# RN831X_RN861X_MCU register map
File version: v0.0.1
CPU: RN831X_RN861X_MCU r1p0, little endian, MPU, no FPU
Registers are 32-bit, read-write, reset 0x0 unless marked. A register's access mark holds for its fields unless they carry their own. Offsets are from the block's base; [hi:lo] are bit positions; {n}, {i} and the like mark numbered series.

## AES_CORE0 — AES module
Base 0x30014000
Same registers: AES_CORE1 0xB0014000
0x00 START — AES Start Register.
  [0] EN
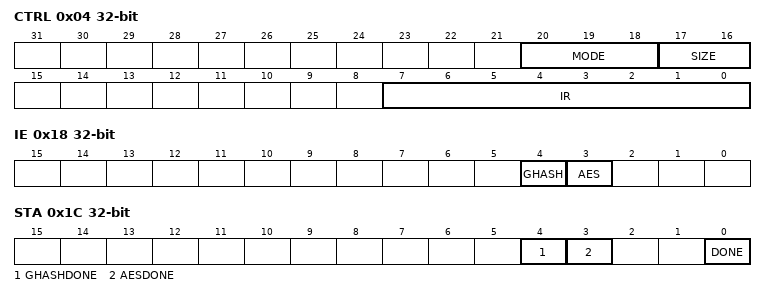
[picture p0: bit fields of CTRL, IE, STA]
0x04 CTRL — AES Control Register.
  [20:18] MODE — Set AES data stream mode.
    0=ECB (AES ECB mode.); 1=CBC (AES CBC mode.); 2=CTR (AES CTR mode.); 3=CFB128 (AES CFB128 mode.); 4=OFB (AES OFB mode.)
  [17:16] SIZE — Set AES key length.
    0=KLEN128 (128 bits AES key); 1=KLEN192 (192 bits AES key); 2=KLEN256 (256 bits AES key)
  [7:0] IR — Set AES calculation methods.
    64=KEYEXP (AES expend key); 66=ENC (AES encryption); 67=DEC (AES decryption); 128=GF128 (GHASH algorithm)
{0x8+4i} IV{i} (i=0..3) — AES IVector Registers.
  [31:0] IV
0x18 IE — AES Interrupt Enable Register.
  [4] GHASH — GHASH calculation complete interrupt.
  [3] AES — AES calculation complete interrupt.
0x1C STA — AES Status Register.
  [4] GHASHDONE write-1-clears — GHASH calculations completed flag.
  [3] AESDONE write-1-clears — AES calculations completed flag.
  [0] DONE write-1-clears — SEA calculations completed flag.
0x20 ADDR — AES Offset Address Configuration Register.
  [17:2] ADDR
{0x24+4i} GHASH_X{i} (i=0..3) — 128-bit GHASH Multiplicand X Registers.
  [31:0] X
{0x34+4i} GHASH_Y{i} (i=0..3) — 128-bit GHASH Multiplier Y Registers.
  [31:0] Y
{0x44+4i} GHASH_Z{i} (i=0..3) — 128-bit GHASH Result Z Registers.
  [31:0] Z

## CRC0_CORE0 — Cyclic Redundancy Check module
Base 0x20070000
Same registers: CRC1 0x20114000, CRC0_CORE1 0xA0070000
0x00 DATA — CRC Data Register.
  [31:0] DATA — CRC data input
0x04 STA — CRC Status Register.
  [0] DONE — CRC status
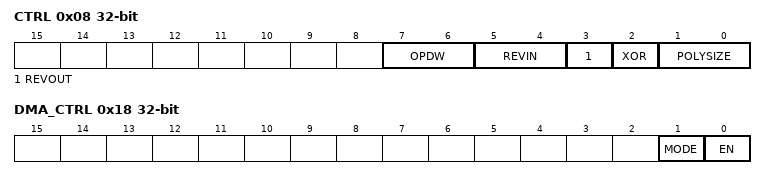
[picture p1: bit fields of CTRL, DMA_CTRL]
0x08 CTRL — CRC Control Register.
  [7:6] OPDW — Configure the data width of CRC operation.
    0=WORD (Set the data width to word.); 1=HWORD (Set the data width to half-word.); 2=BYTE (Set the data width to byte.)
  [5:4] REVIN — Reverse input data.
    0=DEFAULT (No reverse.); 1=BYTE (Reverse data in byte.); 2=HWORD (Reverse data in half-word.); 3=WORD (Reverse data in word.)
  [3] REVOUT — Reverse output data.
  [2] XOR — Enable CRC XOR.
  [1:0] POLYSIZE — Size of polynomial value.
    0=CRC32 (32-bit polynomial.); 1=CRC16 (16-bit polynomial.); 2=CRC8 (8-bit polynomial.); 3=CRC7 (7-bit polynomial.)
0x0C INIT — CRC Init Register.
  [31:0] VAL — CRC init value
0x10 POL — CRC Polynomial Register.
  [31:0] VAL — CRC polynomial value
0x14 XOR — CRC XOR Register.
  [31:0] VAL — CRC XOR value
0x18 DMA_CTRL — CRC DMA Control Register.
  [1] MODE — Set CRC DMA calculation mode
  [0] EN — Enable CRC DMA

## D2F_CORE0 — D2F Module core0
Base 0x2007C000
Same registers: D2F_CORE1 0xA007C000
{0x0+4i} HFCONST{i} access not given reset 0x1000 (i=0..2) — High frequency pulse constant of E{4i:02}~E{4i+3:02}
  [15:0] HFCONST{i} — High frequency pulse constant bits of E{4i:02}~E{4i+3:02}
0x30 CTRL access not given reset 0x1 — D2F control register
  [0] EN — D2F enable bit
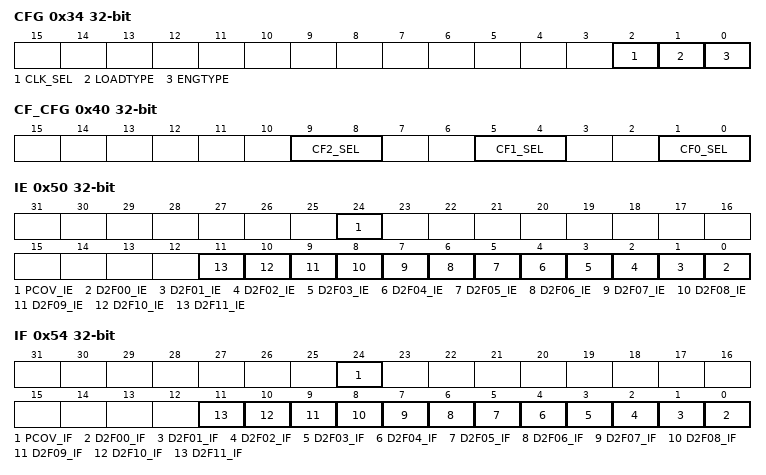
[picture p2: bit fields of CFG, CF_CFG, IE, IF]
0x34 CFG — D2F configeration register
  [2] CLK_SEL — Integrator clk select bit
    0=DEFAULT (Select default D2F clock as integrator clock); 1=CONSTANT (Select constant D2F clock as integrator clock)
  [1] LOADTYPE — Power load type bit
    0=NORMAL (Normal load type of power); 1=SYN_SIMPTC (Synchronized loading type on SimpTC)
  [0] ENGTYPE — Energy register type bit
    0=R2CLR (read to clear); 1=COUNTER (counter after read)
0x40 CF_CFG — CF0~CF2 configeration register
  [9:8] CF2_SEL — Select bit for D2F channel of CF2
    {v}=D2F{v+8:02} (Select D2F{v+8:02} channel as CF2) (v=0..3)
  [5:4] CF1_SEL — Select bit for D2F channel of CF1
    {v}=D2F{v+4:02} (Select D2F{v+4:02} channel as CF1) (v=0..3)
  [1:0] CF0_SEL — Select bit for D2F channel of CF0
    {v}=D2F{v:02} (Select D2F{v:02} channel as CF0) (v=0..3)
0x50 IE — D2F interrupt enable register
  [24] PCOV_IE — Power cover interrupt enable bit
  [n] D2F{n:02}_IE (n=0..11) — D2F{n:02} interrupt enable bit
0x54 IF — D2F interrupt flag register
  [24] PCOV_IF write-1-clears — Power cover interrupt flag bit
  [n] D2F{n:02}_IF write-1-clears (n=0..11) — D2F{n:02} interrupt flag bit
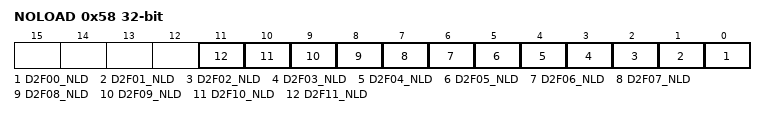
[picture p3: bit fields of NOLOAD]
0x58 NOLOAD read only — No-Load creeping status register
  [n] D2F{n:02}_NLD (n=0..11) — No-Load status flag of D2F{n:02}
{0x60+4i} D2FP{i:02} access not given (i=0..11) — Input power of number {i:02}
  [31:0] D2FP{i:02} — Input power bits of D2F{i:02}
{0x120+4i} D2FE{i:02} access not given (i=0..11) — Output energy of number {i:02}
  [31:0] D2FE{i:02} — Output energy bits of D2F{i:02}
{0x1E0+4i} STARTTH{i:02} access not given (i=0..2) — Start threshold of P{4i:02}~P{4i+3:02}
  [30:0] STARTTh{i:02} — Start threshold bits of D2FP{4i:02}~D2FP{4i+3:02}
